# VPAC0_COMMON_0_IVPAC_TOP_0_CFG_SLV_PAR_VPAC_VISS0_S_VBUSP_VISS_CAC_S_VBUSP_CORE_LUT_CFG_LUT_MEM register map
Vendor: Texas Instruments
Peripheral module from a debugger description file (folder am62A).
Registers are 32-bit, read-write, reset 0x0 unless marked. A register's access mark holds for its fields unless they carry their own. Offsets are as the file gives them; lines under a group give offsets from that group; [hi:lo] are bit positions; {n}, {i} and the like mark numbered series; 'fields as' and 'values as' point back to an identical list; <NAME> marks a mode.

## VPAC0_COMMON_0_IVPAC_TOP_0_CFG_SLV_PAR_VPAC_VISS0_S_VBUSP_VISS_CAC_S_VBUSP_CORE_LUT_CFG_LUT_MEM
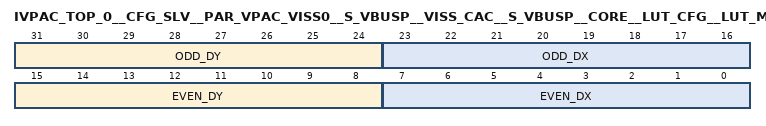
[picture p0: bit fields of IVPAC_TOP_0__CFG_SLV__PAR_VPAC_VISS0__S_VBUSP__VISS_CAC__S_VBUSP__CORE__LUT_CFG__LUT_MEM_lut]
0x00 IVPAC_TOP_0__CFG_SLV__PAR_VPAC_VISS0__S_VBUSP__VISS_CAC__S_VBUSP__CORE__LUT_CFG__LUT_MEM_lut — Only full 32-bit access it allowed for ECC reasons
  [31:24] ODD_DY — Vertical Displacement for Odd Line
  [23:16] ODD_DX — Horizontal Displacement for Odd Line
  [15:8] EVEN_DY — Vertical Displacement for Even Line starting with '0'
  [7:0] EVEN_DX — Horizontal Displacement for Even Line starting with '0'
